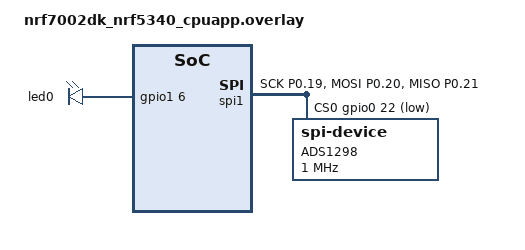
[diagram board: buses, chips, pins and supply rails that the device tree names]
&spi1 {
    status = "okay";
    cs-gpios = <&gpio0 22 GPIO_ACTIVE_LOW>;
    pinctrl-0 = <&ads_spi_default>;
    pinctrl-1 = <&ads_spi_sleep>;
    pinctrl-names = "default", "sleep";

    ads1298@0 {
        compatible = "spi-device";
        reg = <0>;
        spi-max-frequency = <1000000>;
        label = "ADS1298";
        status = "okay";
    };
};

&pinctrl {
    ads_spi_default: ads_spi_default {
        group1 {
            psels = <NRF_PSEL(SPIM_SCK,  0, 19)>,   // SCLK
                    <NRF_PSEL(SPIM_MOSI, 0, 20)>,   // MOSI
                    <NRF_PSEL(SPIM_MISO, 0, 21)>;   // MISO
        };
    };

    ads_spi_sleep: ads_spi_sleep {
        group1 {
            psels = <NRF_PSEL(SPIM_SCK,  0, 19)>,
                    <NRF_PSEL(SPIM_MOSI, 0, 20)>,
                    <NRF_PSEL(SPIM_MISO, 0, 21)>;
            low-power-enable;
        };
    };
};

&led0 {
    gpios = <&gpio1 6 0>;
};
